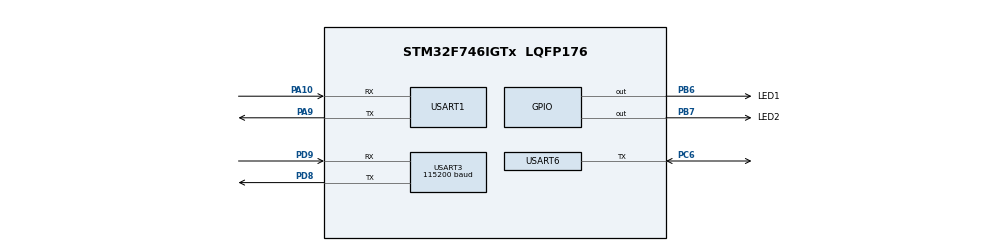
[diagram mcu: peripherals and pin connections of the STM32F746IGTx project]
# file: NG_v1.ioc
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Mcu.Family=STM32F7
NVIC.USART3_IRQn=true\:0\:0\:false\:false\:true\:true\:true
Dma.USART3_RX.0.Instance=DMA1_Stream1
Dma.USART3_TX.1.MemDataAlignment=DMA_MDATAALIGN_BYTE
Dma.USART3_RX.0.PeriphInc=DMA_PINC_DISABLE
PA10.Mode=Asynchronous
Dma.USART6_RX.2.Direction=DMA_PERIPH_TO_MEMORY
Dma.USART3_TX.1.MemInc=DMA_MINC_ENABLE
Dma.USART3_TX.1.PeriphDataAlignment=DMA_PDATAALIGN_BYTE
PC6.Signal=USART6_TX
PB6.GPIO_Label=LED1
PD9.Signal=USART3_RX
PC14/OSC32_IN.Mode=LSE-External-Oscillator
NVIC.DMA1_Stream1_IRQn=true\:0\:0\:false\:false\:true\:false\:true
Dma.USART3_TX.1.Instance=DMA1_Stream3
NVIC.DMA2_Stream1_IRQn=true\:0\:0\:false\:false\:true\:false\:true
PA9.GPIO_PuPd=GPIO_NOPULL
PD9.Mode=Asynchronous
Dma.USART6_RX.2.MemDataAlignment=DMA_MDATAALIGN_BYTE
ProjectManager.StackSize=0x400
Dma.USART3_RX.0.Mode=DMA_CIRCULAR
PA9.GPIO_ModeDefaultPP=GPIO_MODE_AF_PP
NVIC.USART6_IRQn=true\:0\:0\:false\:false\:true\:true\:true
USART3.VirtualMode-Asynchronous=VM_ASYNC
USART1.VirtualMode-Asynchronous=VM_ASYNC
PA13.Signal=SYS_JTMS-SWDIO
PA9.Mode=Asynchronous
USART3.BaudRate=115200
ProjectManager.TargetToolchain=STM32CubeIDE
Dma.USART6_RX.2.MemInc=DMA_MINC_ENABLE
PC6.Mode=Half_duplex(single_wire_mode)
PH0/OSC_IN.Mode=HSE-External-Oscillator
PA9.Signal=USART1_TX
PB6.Signal=GPIO_Output
PH1/OSC_OUT.Signal=RCC_OSC_OUT
Dma.USART6_RX.2.Instance=DMA2_Stream1
Dma.USART6_RX.2.PeriphDataAlignment=DMA_PDATAALIGN_BYTE
PD8.Signal=USART3_TX
RCC.USBFreq_Value=96000000
PC6.GPIO_ModeDefaultOD=GPIO_MODE_AF_OD
PD8.Mode=Asynchronous
RCC.HSE_VALUE=25000000
Dma.USART3_RX.0.MemDataAlignment=DMA_MDATAALIGN_BYTE
board=custom
Dma.USART3_TX.1.Mode=DMA_NORMAL
RCC.VCOOutputFreq_Value=192000000
Dma.USART6_RX.2.FIFOMode=DMA_FIFOMODE_DISABLE
Dma.USART6_RX.2.Mode=DMA_NORMAL
Dma.USART6_RX.2.Priority=DMA_PRIORITY_MEDIUM
PH0/OSC_IN.Signal=RCC_OSC_IN
PA14.Mode=Serial_Wire
Dma.USART3_RX.0.PeriphDataAlignment=DMA_PDATAALIGN_BYTE
PB7.Signal=GPIO_Output
Dma.USART3_RX.0.FIFOMode=DMA_FIFOMODE_DISABLE
PA13.Mode=Serial_Wire
PH1/OSC_OUT.Mode=HSE-External-Oscillator
Mcu.Name=STM32F746IGTx
Dma.USART3_TX.1.FIFOMode=DMA_FIFOMODE_DISABLE
Dma.USART3_TX.1.Priority=DMA_PRIORITY_VERY_HIGH
PB7.GPIO_Label=LED2
Dma.USART3_RX.0.Direction=DMA_PERIPH_TO_MEMORY
Mcu.Package=LQFP176
Dma.USART3_RX.0.Priority=DMA_PRIORITY_VERY_HIGH
PC14/OSC32_IN.Signal=RCC_OSC32_IN
PC15/OSC32_OUT.Mode=LSE-External-Oscillator
PA10.Signal=USART1_RX
PA14.Signal=SYS_JTCK-SWCLK
ProjectManager.HeapSize=0x200
USART6.BaudRate=57600
PC6.GPIO_PuPd=GPIO_PULLUP
Dma.USART3_RX.0.MemInc=DMA_MINC_ENABLE
RCC.HSI_VALUE=16000000
USART6.VirtualMode-Half_duplex(single_wire_mode)=VM_ASYNC
NVIC.PriorityGroup=NVIC_PRIORITYGROUP_4
Dma.USART3_TX.1.Direction=DMA_MEMORY_TO_PERIPH
Dma.Request2=USART6_RX
Dma.Request1=USART3_TX
NVIC.DMA1_Stream3_IRQn=true\:0\:0\:false\:false\:true\:false\:true
PC15/OSC32_OUT.Signal=RCC_OSC32_OUT
Dma.USART3_TX.1.PeriphInc=DMA_PINC_DISABLE
Dma.USART6_RX.2.PeriphInc=DMA_PINC_DISABLE
Dma.Request0=USART3_RX
PC6.GPIO_Speed=GPIO_SPEED_FREQ_HIGH

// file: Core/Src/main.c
/* USER CODE BEGIN Header */
/**
  ******************************************************************************
  * @file           : main.c
  * @brief          : Main program body
  ******************************************************************************
  * @attention
  *
  * <h2><center>&copy; Copyright (c) 2021 STMicroelectronics.
  * All rights reserved.</center></h2>
  *
  * This software component is licensed by ST under BSD 3-Clause license,
  * the "License"; You may not use this file except in compliance with the
  * License. You may obtain a copy of the License at:
  *                        opensource.org/licenses/BSD-3-Clause
  *
  ******************************************************************************
  */
/* USER CODE END Header */
#include "main.h"

/* USER CODE BEGIN Includes */
#include "mainpp.h"
#include "xl430.h"
/* USER CODE END Includes */

UART_HandleTypeDef huart1;
UART_HandleTypeDef huart3;
UART_HandleTypeDef huart6;
DMA_HandleTypeDef hdma_usart3_rx;
DMA_HandleTypeDef hdma_usart3_tx;
DMA_HandleTypeDef hdma_usart6_rx;

void SystemClock_Config(void);
static void MX_GPIO_Init(void);
static void MX_DMA_Init(void);
static void MX_USART3_UART_Init(void);
static void MX_USART6_UART_Init(void);
static void MX_USART1_UART_Init(void);

int main(void)
{

  /* MCU Configuration--------------------------------------------------------*/

  /* Reset of all peripherals, Initializes the Flash interface and the Systick. */
  HAL_Init();

  /* Configure the system clock */
  SystemClock_Config();

  /* Initialize all configured peripherals */
  MX_GPIO_Init();
  MX_DMA_Init();
  MX_USART3_UART_Init();
  MX_USART6_UART_Init();
  MX_USART1_UART_Init();
  /* USER CODE BEGIN 2 */

  // servo setup
  if(xl430_debug_uart_init(&huart1) != HAL_OK)
      		  {
      			  Error_Handler();
      		  }
  xl430_int(&huart6);
  setup();
  /* USER CODE END 2 */

  /* Infinite loop */
  /* USER CODE BEGIN WHILE */
  while (1)
  {
	//  HAL_GPIO_TogglePin(LED1_GPIO_Port, LED1_Pin);
	  loop();

    /* USER CODE END WHILE */

  }
}

void SystemClock_Config(void)
{
  RCC_OscInitTypeDef RCC_OscInitStruct = {0};
  RCC_ClkInitTypeDef RCC_ClkInitStruct = {0};
  RCC_PeriphCLKInitTypeDef PeriphClkInitStruct = {0};

  /** Configure LSE Drive Capability
  */
  HAL_PWR_EnableBkUpAccess();
  /** Configure the main internal regulator output voltage
  */
  __HAL_RCC_PWR_CLK_ENABLE();
  __HAL_PWR_VOLTAGESCALING_CONFIG(PWR_REGULATOR_VOLTAGE_SCALE3);
  /** Initializes the RCC Oscillators according to the specified parameters
  * in the RCC_OscInitTypeDef structure.
  */
  RCC_OscInitStruct.OscillatorType = RCC_OSCILLATORTYPE_HSI;
  RCC_OscInitStruct.HSIState = RCC_HSI_ON;
  RCC_OscInitStruct.HSICalibrationValue = RCC_HSICALIBRATION_DEFAULT;
  RCC_OscInitStruct.PLL.PLLState = RCC_PLL_NONE;
  if (HAL_RCC_OscConfig(&RCC_OscInitStruct) != HAL_OK)
  {
    Error_Handler();
  }
  /** Initializes the CPU, AHB and APB buses clocks
  */
  RCC_ClkInitStruct.ClockType = RCC_CLOCKTYPE_HCLK|RCC_CLOCKTYPE_SYSCLK
                              |RCC_CLOCKTYPE_PCLK1|RCC_CLOCKTYPE_PCLK2;
  RCC_ClkInitStruct.SYSCLKSource = RCC_SYSCLKSOURCE_HSI;
  RCC_ClkInitStruct.AHBCLKDivider = RCC_SYSCLK_DIV1;
  RCC_ClkInitStruct.APB1CLKDivider = RCC_HCLK_DIV1;
  RCC_ClkInitStruct.APB2CLKDivider = RCC_HCLK_DIV1;

  if (HAL_RCC_ClockConfig(&RCC_ClkInitStruct, FLASH_LATENCY_0) != HAL_OK)
  {
    Error_Handler();
  }
  PeriphClkInitStruct.PeriphClockSelection = RCC_PERIPHCLK_USART1|RCC_PERIPHCLK_USART3
                              |RCC_PERIPHCLK_USART6;
  PeriphClkInitStruct.Usart1ClockSelection = RCC_USART1CLKSOURCE_PCLK2;
  PeriphClkInitStruct.Usart3ClockSelection = RCC_USART3CLKSOURCE_PCLK1;
  PeriphClkInitStruct.Usart6ClockSelection = RCC_USART6CLKSOURCE_PCLK2;
  if (HAL_RCCEx_PeriphCLKConfig(&PeriphClkInitStruct) != HAL_OK)
  {
    Error_Handler();
  }
}

static void MX_USART1_UART_Init(void)
{

  huart1.Instance = USART1;
  huart1.Init.BaudRate = 115200;
  huart1.Init.WordLength = UART_WORDLENGTH_8B;
  huart1.Init.StopBits = UART_STOPBITS_1;
  huart1.Init.Parity = UART_PARITY_NONE;
  huart1.Init.Mode = UART_MODE_TX_RX;
  huart1.Init.HwFlowCtl = UART_HWCONTROL_NONE;
  huart1.Init.OverSampling = UART_OVERSAMPLING_16;
  huart1.Init.OneBitSampling = UART_ONE_BIT_SAMPLE_DISABLE;
  huart1.AdvancedInit.AdvFeatureInit = UART_ADVFEATURE_NO_INIT;
  if (HAL_UART_Init(&huart1) != HAL_OK)
  {
    Error_Handler();
  }

}

static void MX_USART3_UART_Init(void)
{

  huart3.Instance = USART3;
  huart3.Init.BaudRate = 115200;
  huart3.Init.WordLength = UART_WORDLENGTH_8B;
  huart3.Init.StopBits = UART_STOPBITS_1;
  huart3.Init.Parity = UART_PARITY_NONE;
  huart3.Init.Mode = UART_MODE_TX_RX;
  huart3.Init.HwFlowCtl = UART_HWCONTROL_NONE;
  huart3.Init.OverSampling = UART_OVERSAMPLING_16;
  huart3.Init.OneBitSampling = UART_ONE_BIT_SAMPLE_DISABLE;
  huart3.AdvancedInit.AdvFeatureInit = UART_ADVFEATURE_NO_INIT;
  if (HAL_UART_Init(&huart3) != HAL_OK)
  {
    Error_Handler();
  }

}

static void MX_USART6_UART_Init(void)
{

  huart6.Instance = USART6;
  huart6.Init.BaudRate = 57600;
  huart6.Init.WordLength = UART_WORDLENGTH_8B;
  huart6.Init.StopBits = UART_STOPBITS_1;
  huart6.Init.Parity = UART_PARITY_NONE;
  huart6.Init.Mode = UART_MODE_TX_RX;
  huart6.Init.HwFlowCtl = UART_HWCONTROL_NONE;
  huart6.Init.OverSampling = UART_OVERSAMPLING_16;
  huart6.Init.OneBitSampling = UART_ONE_BIT_SAMPLE_DISABLE;
  huart6.AdvancedInit.AdvFeatureInit = UART_ADVFEATURE_NO_INIT;
  if (HAL_HalfDuplex_Init(&huart6) != HAL_OK)
  {
    Error_Handler();
  }

}

static void MX_DMA_Init(void)
{

  /* DMA controller clock enable */
  __HAL_RCC_DMA1_CLK_ENABLE();
  __HAL_RCC_DMA2_CLK_ENABLE();

  /* DMA interrupt init */
  /* DMA1_Stream1_IRQn interrupt configuration */
  HAL_NVIC_SetPriority(DMA1_Stream1_IRQn, 0, 0);
  HAL_NVIC_EnableIRQ(DMA1_Stream1_IRQn);
  /* DMA1_Stream3_IRQn interrupt configuration */
  HAL_NVIC_SetPriority(DMA1_Stream3_IRQn, 0, 0);
  HAL_NVIC_EnableIRQ(DMA1_Stream3_IRQn);
  /* DMA2_Stream1_IRQn interrupt configuration */
  HAL_NVIC_SetPriority(DMA2_Stream1_IRQn, 0, 0);
  HAL_NVIC_EnableIRQ(DMA2_Stream1_IRQn);

}

static void MX_GPIO_Init(void)
{
  GPIO_InitTypeDef GPIO_InitStruct = {0};

  /* GPIO Ports Clock Enable */
  __HAL_RCC_GPIOC_CLK_ENABLE();
  __HAL_RCC_GPIOH_CLK_ENABLE();
  __HAL_RCC_GPIOD_CLK_ENABLE();
  __HAL_RCC_GPIOA_CLK_ENABLE();
  __HAL_RCC_GPIOB_CLK_ENABLE();

  /*Configure GPIO pin Output Level */
  HAL_GPIO_WritePin(GPIOB, LED1_Pin|LED2_Pin, GPIO_PIN_RESET);

  /*Configure GPIO pins : LED1_Pin LED2_Pin */
  GPIO_InitStruct.Pin = LED1_Pin|LED2_Pin;
  GPIO_InitStruct.Mode = GPIO_MODE_OUTPUT_PP;
  GPIO_InitStruct.Pull = GPIO_NOPULL;
  GPIO_InitStruct.Speed = GPIO_SPEED_FREQ_LOW;
  HAL_GPIO_Init(GPIOB, &GPIO_InitStruct);

}

void Error_Handler(void)
{
  /* USER CODE BEGIN Error_Handler_Debug */
  /* User can add his own implementation to report the HAL error return state */
  __disable_irq();
  while (1)
  {
	  HAL_GPIO_TogglePin(LED1_GPIO_Port, LED1_Pin);
	  HAL_Delay(100);
  }
  /* USER CODE END Error_Handler_Debug */
}

/************************ (C) COPYRIGHT STMicroelectronics *****END OF FILE****/
